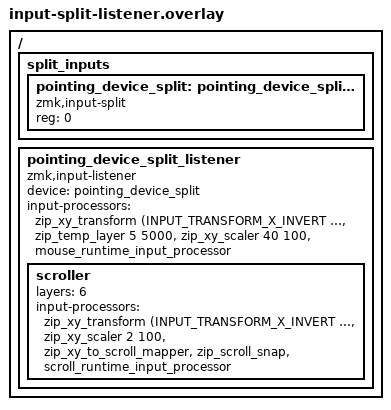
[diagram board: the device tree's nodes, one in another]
#include <scroll-snap.dtsi>
#include <dt-bindings/zmk/input_transform.h>
#include <input/processors/runtime-input-processor.dtsi>
/{
    split_inputs {
        #address-cells = <1>;
        #size-cells = <0>;

        pointing_device_split: pointing_device_split@0 {
            compatible = "zmk,input-split";
            reg = <0>;
        };
    };

    pointing_device_split_listener: pointing_device_split_listener {
        compatible = "zmk,input-listener";
        device = <&pointing_device_split>;
        status = "okay";
        input-processors = 
            <&zip_xy_transform (INPUT_TRANSFORM_X_INVERT | INPUT_TRANSFORM_Y_INVERT)>,
            <&zip_temp_layer 5 5000>,
            <&zip_xy_scaler 40 100>,
            <&mouse_runtime_input_processor>;

        scroller {
            layers = <6>;
            input-processors =
                <&zip_xy_transform (INPUT_TRANSFORM_X_INVERT | INPUT_TRANSFORM_Y_INVERT)>,
                <&zip_xy_scaler 2 100>,
                <&zip_xy_to_scroll_mapper>,
                <&zip_scroll_snap>,
                <&scroll_runtime_input_processor>;
        };
     };
};
